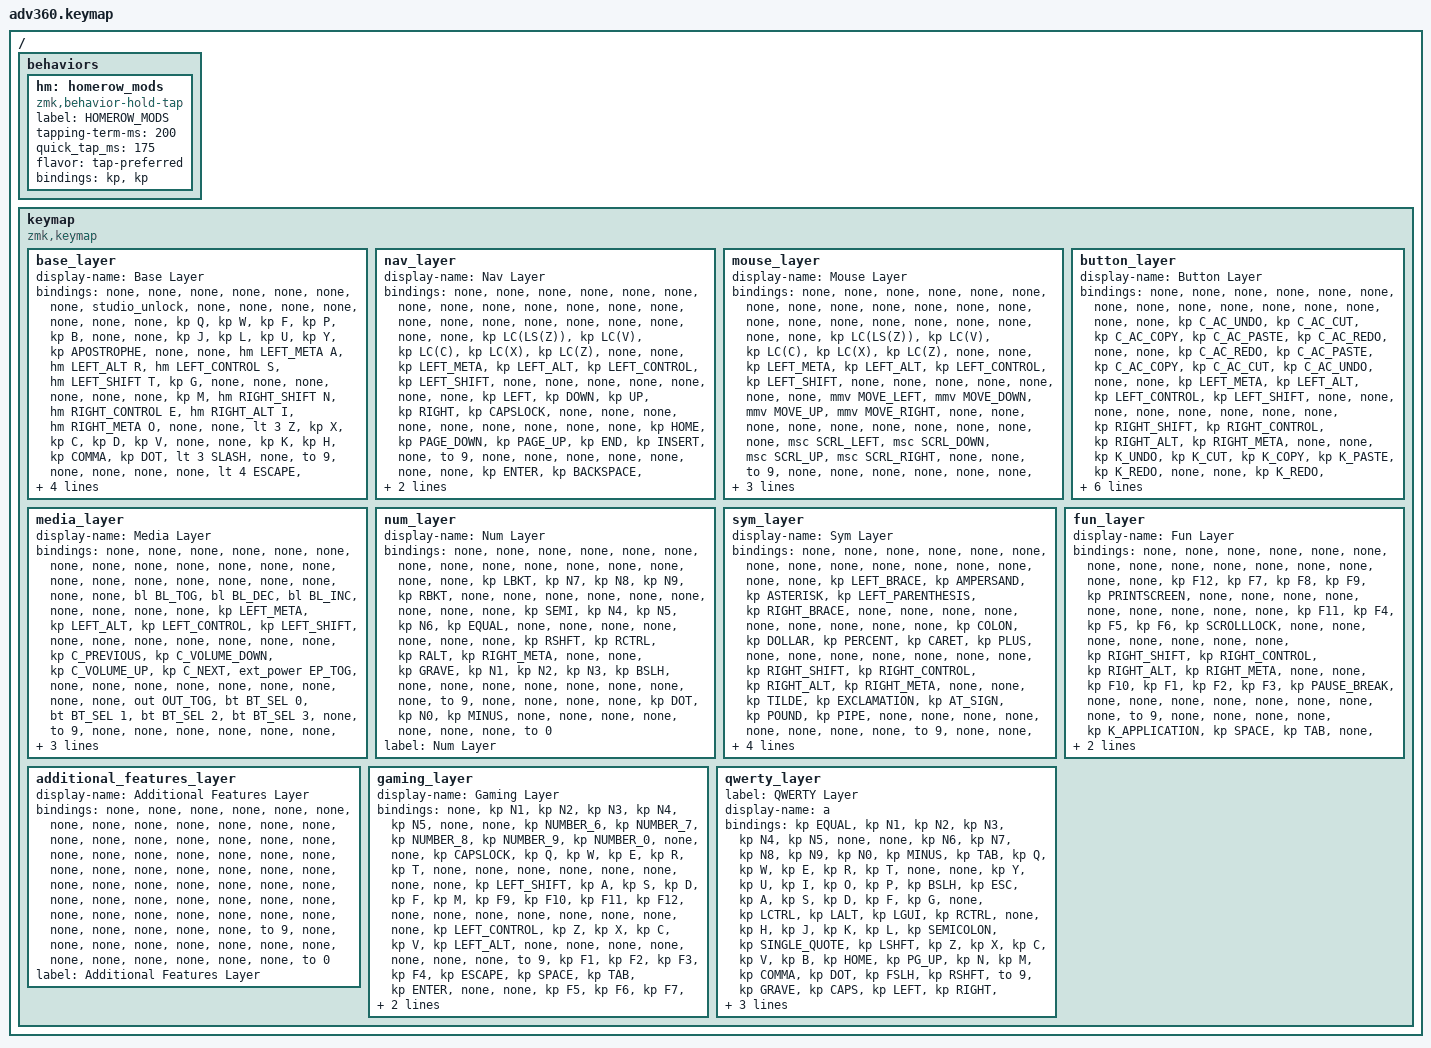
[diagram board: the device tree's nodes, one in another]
#include <dt-bindings/zmk/stp.h>
#include <behaviors.dtsi>
#include <dt-bindings/zmk/backlight.h>
#include <dt-bindings/zmk/bt.h>
#include <dt-bindings/zmk/ext_power.h>
#include <dt-bindings/zmk/keys.h>
#include <dt-bindings/zmk/outputs.h>
#include <dt-bindings/zmk/pointing.h>

/ {
    behaviors {
        #include "macros.dtsi"
      #include "version.dtsi"

        hm: homerow_mods {
            compatible = "zmk,behavior-hold-tap";
            label = "HOMEROW_MODS";
            #binding-cells = <2>;
            tapping-term-ms = <200>;
            quick_tap_ms = <175>;
            flavor = "tap-preferred";
            bindings = <&kp>, <&kp>;
        };
    };

    keymap {
        compatible = "zmk,keymap";

        base_layer {
            display-name = "Base Layer";
            bindings = <
&none  &none            &none           &none               &none             &none  &none                                                                                      &studio_unlock  &none  &none              &none                &none            &none             &none
&none  &kp Q            &kp W           &kp F               &kp P             &kp B  &none                                                                                      &none           &kp J  &kp L              &kp U                &kp Y            &kp APOSTROPHE    &none
&none  &hm LEFT_META A  &hm LEFT_ALT R  &hm LEFT_CONTROL S  &hm LEFT_SHIFT T  &kp G  &none                &none        &none        &none        &none                          &none           &kp M  &hm RIGHT_SHIFT N  &hm RIGHT_CONTROL E  &hm RIGHT_ALT I  &hm RIGHT_META O  &none
&none  &lt 3 Z          &kp X           &kp C               &kp D             &kp V                                    &none        &none                                                       &kp K  &kp H              &kp COMMA            &kp DOT          &lt 3 SLASH       &none
&to 9  &none            &none           &none               &none                           &lt 4 ESCAPE  &lt 1 SPACE  &lt 2 TAB    &lt 6 ENTER  &lt 5 BACKSPACE  &lt 7 DELETE                         &none              &none                &none            &none             &to 10
            >;

            label = "Base Layer";
        };

        nav_layer {
            display-name = "Nav Layer";
            bindings = <
&none  &none          &none         &none             &none           &none  &none                                                               &none  &none          &none          &none        &none      &none         &none
&none  &none          &none         &none             &none           &none  &none                                                               &none  &kp LC(LS(Z))  &kp LC(V)      &kp LC(C)    &kp LC(X)  &kp LC(Z)     &none
&none  &kp LEFT_META  &kp LEFT_ALT  &kp LEFT_CONTROL  &kp LEFT_SHIFT  &none  &none         &none  &none    &none      &none                      &none  &kp LEFT       &kp DOWN       &kp UP       &kp RIGHT  &kp CAPSLOCK  &none
&none  &none          &none         &none             &none           &none                       &none    &none                                        &kp HOME       &kp PAGE_DOWN  &kp PAGE_UP  &kp END    &kp INSERT    &none
&to 9  &none          &none         &none             &none                         &none  &none  &none    &kp ENTER  &kp BACKSPACE  &kp DELETE                        &none          &none        &none      &none         &to 0
            >;

            label = "Nav Layer";
        };

        mouse_layer {
            display-name = "Mouse Layer";
            bindings = <
&none  &none          &none         &none             &none           &none  &none                                                          &none  &none           &none           &none         &none            &none      &none
&none  &none          &none         &none             &none           &none  &none                                                          &none  &kp LC(LS(Z))   &kp LC(V)       &kp LC(C)     &kp LC(X)        &kp LC(Z)  &none
&none  &kp LEFT_META  &kp LEFT_ALT  &kp LEFT_CONTROL  &kp LEFT_SHIFT  &none  &none         &none  &none    &none      &none                 &none  &mmv MOVE_LEFT  &mmv MOVE_DOWN  &mmv MOVE_UP  &mmv MOVE_RIGHT  &none      &none
&none  &none          &none         &none             &none           &none                       &none    &none                                   &msc SCRL_LEFT  &msc SCRL_DOWN  &msc SCRL_UP  &msc SCRL_RIGHT  &none      &none
&to 9  &none          &none         &none             &none                         &none  &none  &none    &mkp RCLK  &mkp LCLK  &mkp MCLK                         &none           &none         &none            &none      &to 0
            >;

            label = "Mouse Layer";
        };

        button_layer {
            display-name = "Button Layer";
            bindings = <
&none  &none          &none         &none             &none           &none          &none                                                                      &none  &none          &none            &none              &none          &none           &none
&none  &kp C_AC_UNDO  &kp C_AC_CUT  &kp C_AC_COPY     &kp C_AC_PASTE  &kp C_AC_REDO  &none                                                                      &none  &kp C_AC_REDO  &kp C_AC_PASTE   &kp C_AC_COPY      &kp C_AC_CUT   &kp C_AC_UNDO   &none
&none  &kp LEFT_META  &kp LEFT_ALT  &kp LEFT_CONTROL  &kp LEFT_SHIFT  &none          &none             &none      &none        &none      &none                 &none  &none          &kp RIGHT_SHIFT  &kp RIGHT_CONTROL  &kp RIGHT_ALT  &kp RIGHT_META  &none
&none  &kp K_UNDO     &kp K_CUT     &kp K_COPY        &kp K_PASTE     &kp K_REDO                                  &none        &none                                   &kp K_REDO     &kp K_PASTE      &kp K_COPY         &kp K_CUT      &kp K_UNDO      &none
&to 9  &none          &none         &none             &none                                 &mkp MCLK  &mkp LCLK  &mkp RCLK    &mkp RCLK  &mkp LCLK  &mkp MCLK                        &none            &none              &none          &none           &to 0
            >;

            label = "Button Layer";
        };

        media_layer {
            display-name = "Media Layer";
            bindings = <
&none  &none          &none         &none             &none           &none  &none                                                                   &none  &none           &none              &none            &none         &none              &none
&none  &none          &none         &none             &none           &none  &none                                                                   &none  &bl BL_TOG      &bl BL_DEC         &bl BL_INC       &none         &none              &none
&none  &kp LEFT_META  &kp LEFT_ALT  &kp LEFT_CONTROL  &kp LEFT_SHIFT  &none  &none         &none  &none    &none       &none                         &none  &kp C_PREVIOUS  &kp C_VOLUME_DOWN  &kp C_VOLUME_UP  &kp C_NEXT    &ext_power EP_TOG  &none
&none  &none          &none         &none             &none           &none                       &none    &none                                            &out OUT_TOG    &bt BT_SEL 0       &bt BT_SEL 1     &bt BT_SEL 2  &bt BT_SEL 3       &none
&to 9  &none          &none         &none             &none                         &none  &none  &none    &kp C_STOP  &kp C_PLAY_PAUSE  &kp C_MUTE                         &none              &none            &none         &none              &to 0
            >;

            label = "Media Layer";
        };

        num_layer {
            display-name = "Num Layer";
            bindings = <
&none  &none      &none   &none   &none   &none      &none                                                     &none  &none  &none      &none      &none     &none           &none
&none  &kp LBKT   &kp N7  &kp N8  &kp N9  &kp RBKT   &none                                                     &none  &none  &none      &none      &none     &none           &none
&none  &kp SEMI   &kp N4  &kp N5  &kp N6  &kp EQUAL  &none           &none   &none        &none  &none         &none  &none  &kp RSHFT  &kp RCTRL  &kp RALT  &kp RIGHT_META  &none
&none  &kp GRAVE  &kp N1  &kp N2  &kp N3  &kp BSLH                           &none        &none                       &none  &none      &none      &none     &none           &none
&to 9  &none      &none   &none   &none                     &kp DOT  &kp N0  &kp MINUS    &none  &none  &none                &none      &none      &none     &none           &to 0
            >;

            label = "Num Layer";
        };

        sym_layer {
            display-name = "Sym Layer";
            bindings = <
&none  &none           &none            &none         &none                 &none            &none                                                                                      &none  &none  &none            &none              &none          &none           &none
&none  &kp LEFT_BRACE  &kp AMPERSAND    &kp ASTERISK  &kp LEFT_PARENTHESIS  &kp RIGHT_BRACE  &none                                                                                      &none  &none  &none            &none              &none          &none           &none
&none  &kp COLON       &kp DOLLAR       &kp PERCENT   &kp CARET             &kp PLUS         &none                        &none                  &none             &none  &none         &none  &none  &kp RIGHT_SHIFT  &kp RIGHT_CONTROL  &kp RIGHT_ALT  &kp RIGHT_META  &none
&none  &kp TILDE       &kp EXCLAMATION  &kp AT_SIGN   &kp POUND             &kp PIPE                                                             &none             &none                       &none  &none            &none              &none          &none           &none
&to 9  &none           &none            &none         &none                                         &kp LEFT_PARENTHESIS  &kp RIGHT_PARENTHESIS  &kp UNDERSCORE    &none  &none  &none                &none            &none              &none          &none           &to 0
            >;

            label = "Sym Layer";
        };

        fun_layer {
            display-name = "Fun Layer";
            bindings = <
&none  &none    &none   &none   &none   &none            &none                                                                &none  &none  &none            &none              &none          &none           &none
&none  &kp F12  &kp F7  &kp F8  &kp F9  &kp PRINTSCREEN  &none                                                                &none  &none  &none            &none              &none          &none           &none
&none  &kp F11  &kp F4  &kp F5  &kp F6  &kp SCROLLLOCK   &none                     &none      &none      &none  &none         &none  &none  &kp RIGHT_SHIFT  &kp RIGHT_CONTROL  &kp RIGHT_ALT  &kp RIGHT_META  &none
&none  &kp F10  &kp F1  &kp F2  &kp F3  &kp PAUSE_BREAK                                       &none      &none                       &none  &none            &none              &none          &none           &none
&to 9  &none    &none   &none   &none                           &kp K_APPLICATION  &kp SPACE  &kp TAB    &none  &none  &none                &none            &none              &none          &none           &to 0
            >;

            label = "Fun Layer";
        };

        additional_features_layer {
            display-name = "Additional Features Layer";
            bindings = <
&none  &none  &none  &none  &none  &none  &none                                              &none  &none  &none  &none  &none  &none  &none
&none  &none  &none  &none  &none  &none  &none                                              &none  &none  &none  &none  &none  &none  &none
&none  &none  &none  &none  &none  &none  &none         &none  &none    &none  &none         &none  &none  &none  &none  &none  &none  &none
&none  &none  &none  &none  &none  &none                       &none    &none                       &none  &none  &none  &none  &none  &none
&to 9  &none  &none  &none  &none                &none  &none  &none    &none  &none  &none                &none  &none  &none  &none  &to 0
            >;

            label = "Additional Features Layer";
        };

        gaming_layer {
            display-name = "Gaming Layer";
            bindings = <
&none  &kp N1            &kp N2  &kp N3  &kp N4  &kp N5  &none                                                                    &none  &kp NUMBER_6  &kp NUMBER_7  &kp NUMBER_8  &kp NUMBER_9  &kp NUMBER_0  &none
&none  &kp CAPSLOCK      &kp Q   &kp W   &kp E   &kp R   &kp T                                                                    &none  &none         &none         &none         &none         &none         &none
&none  &kp LEFT_SHIFT    &kp A   &kp S   &kp D   &kp F   &kp M              &kp F9     &kp F10         &kp F11    &kp F12         &none  &none         &none         &none         &none         &none         &none
&none  &kp LEFT_CONTROL  &kp Z   &kp X   &kp C   &kp V                                 &kp LEFT_ALT    &none                             &none         &none         &none         &none         &none         &none
&to 9  &kp F1            &kp F2  &kp F3  &kp F4                 &kp ESCAPE  &kp SPACE  &kp TAB         &kp ENTER  &none    &none                       &kp F5        &kp F6        &kp F7        &kp F8        &to 0
            >;

            label = "Gaming Layer";
        };

        qwerty_layer {
            label = "QWERTY Layer";
            display-name = "a";
            bindings = <
&kp EQUAL  &kp N1     &kp N2    &kp N3    &kp N4     &kp N5  &none                                                                                      &none  &kp N6  &kp N7  &kp N8     &kp N9    &kp N0         &kp MINUS
&kp TAB    &kp Q      &kp W     &kp E     &kp R      &kp T   &none                                                                                      &none  &kp Y   &kp U   &kp I      &kp O     &kp P          &kp BSLH
&kp ESC    &kp A      &kp S     &kp D     &kp F      &kp G   &none                &kp LCTRL    &kp LALT     &kp LGUI     &kp RCTRL                      &none  &kp H   &kp J   &kp K      &kp L     &kp SEMICOLON  &kp SINGLE_QUOTE
&kp LSHFT  &kp Z      &kp X     &kp C     &kp V      &kp B                                     &kp HOME     &kp PG_UP                                          &kp N   &kp M   &kp COMMA  &kp DOT   &kp FSLH       &kp RSHFT
&to 9      &kp GRAVE  &kp CAPS  &kp LEFT  &kp RIGHT                 &lt 4 ESCAPE  &lt 1 SPACE  &lt 2 TAB    &lt 6 ENTER  &lt 5 BACKSPACE  &lt 7 DELETE                 &kp UP  &kp DOWN   &kp LBKT  &kp RBKT       &to 0
            >;

            label = "QWERTY Layer";
        };
    };
};
